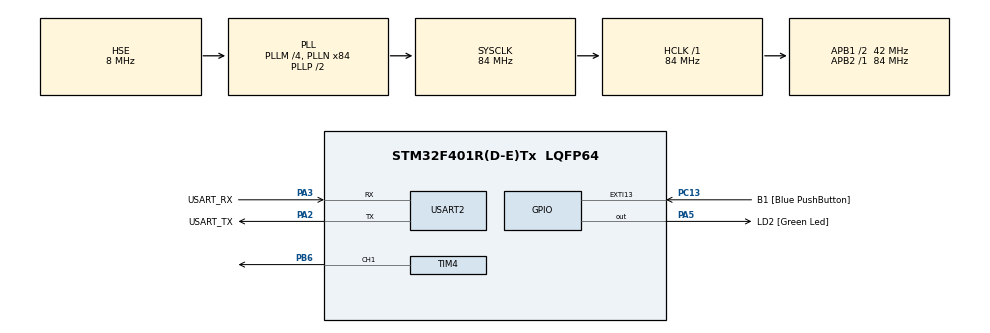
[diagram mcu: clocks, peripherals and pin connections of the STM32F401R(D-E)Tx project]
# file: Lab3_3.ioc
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Mcu.Family=STM32F4
Mcu.Name=STM32F401R(D-E)Tx
Mcu.Package=LQFP64
NVIC.PriorityGroup=NVIC_PRIORITYGROUP_2
NVIC.TIM1_UP_TIM10_IRQn=true\:2\:0\:true\:false\:true\:true\:true\:true
NVIC.TIM3_IRQn=true\:2\:0\:true\:false\:true\:true\:true\:true
NVIC.TIM4_IRQn=true\:2\:0\:true\:false\:true\:true\:true\:true
PA13.GPIO_Label=TMS
PA13.Mode=Serial_Wire
PA13.Signal=SYS_JTMS-SWDIO
PA14.GPIO_Label=TCK
PA14.Mode=Serial_Wire
PA14.Signal=SYS_JTCK-SWCLK
PA2.GPIO_Label=USART_TX
PA2.GPIO_Mode=GPIO_MODE_AF_PP
PA2.GPIO_PuPd=GPIO_NOPULL
PA2.GPIO_Speed=GPIO_SPEED_FREQ_LOW
PA2.Mode=Asynchronous
PA2.Signal=USART2_TX
PA3.GPIO_Label=USART_RX
PA3.GPIO_Mode=GPIO_MODE_AF_PP
PA3.GPIO_PuPd=GPIO_NOPULL
PA3.GPIO_Speed=GPIO_SPEED_FREQ_LOW
PA3.Mode=Asynchronous
PA3.Signal=USART2_RX
PA5.GPIO_Label=LD2 [Green Led]
PA5.GPIO_Mode=GPIO_MODE_OUTPUT_PP
PA5.GPIO_PuPd=GPIO_NOPULL
PA5.GPIO_Speed=GPIO_SPEED_FREQ_LOW
PA5.Signal=GPIO_Output
PB3.GPIO_Label=SWO
PB3.Signal=SYS_JTDO-SWO
PB6.Signal=S_TIM4_CH1
PC13-ANTI_TAMP.GPIO_Label=B1 [Blue PushButton]
PC13-ANTI_TAMP.GPIO_ModeDefaultEXTI=GPIO_MODE_IT_FALLING
PC13-ANTI_TAMP.GPIO_PuPd=GPIO_NOPULL
PC13-ANTI_TAMP.Signal=GPXTI13
PC14-OSC32_IN.Mode=LSE-External-Oscillator
PC14-OSC32_IN.Signal=RCC_OSC32_IN
PC15-OSC32_OUT.Mode=LSE-External-Oscillator
PC15-OSC32_OUT.Signal=RCC_OSC32_OUT
PH0\ -\ OSC_IN.Mode=HSE-External-Clock-Source
PH0\ -\ OSC_IN.Signal=RCC_OSC_IN
PH1\ -\ OSC_OUT.Mode=HSE-External-Clock-Source
PH1\ -\ OSC_OUT.Signal=RCC_OSC_OUT
ProjectManager.HeapSize=0x200
ProjectManager.StackSize=0x400
ProjectManager.TargetToolchain=STM32CubeIDE
RCC.48MHZClocksFreq_Value=24000000
RCC.AHBFreq_Value=84000000
RCC.APB1CLKDivider=RCC_HCLK_DIV2
RCC.APB1Freq_Value=42000000
RCC.APB1TimFreq_Value=84000000
RCC.APB2Freq_Value=84000000
RCC.APB2TimFreq_Value=84000000
RCC.CortexFreq_Value=84000000
RCC.HCLKFreq_Value=84000000
RCC.HSE_VALUE=8000000
RCC.HSI_VALUE=16000000
RCC.PLLM=4
RCC.PLLN=84
RCC.PLLQ=7
RCC.PLLSourceVirtual=RCC_PLLSOURCE_HSE
RCC.SYSCLKFreq_VALUE=84000000
RCC.SYSCLKSource=RCC_SYSCLKSOURCE_PLLCLK
RCC.VCOOutputFreq_Value=168000000
SH.S_TIM4_CH1.0=TIM4_CH1,PWM Generation1 CH1
TIM10.Period=9998
TIM10.Prescaler=8399
TIM3.Period=4904
TIM3.Prescaler=8399
TIM4.Channel-PWM\ Generation1\ CH1=TIM_CHANNEL_1
TIM4.Period=4999
TIM4.Prescaler=8399
USART2.VirtualMode=VM_ASYNC
VP_TIM10_VS_ClockSourceINT.Mode=Enable_Timer
VP_TIM3_VS_ClockSourceINT.Mode=Internal
VP_TIM4_VS_ClockSourceINT.Mode=Internal
board=NUCLEO-F401RE

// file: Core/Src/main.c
/* USER CODE BEGIN Header */
/**
  ******************************************************************************
  * @file           : main.c
  * @brief          : Main program body
  ******************************************************************************
  * @attention
  *
  * Copyright (c) 2023 STMicroelectronics.
  * All rights reserved.
  *
  * This software is licensed under terms that can be found in the LICENSE file
  * in the root directory of this software component.
  * If no LICENSE file comes with this software, it is provided AS-IS.
  *
  ******************************************************************************
  */
/* USER CODE END Header */
#include "main.h"

TIM_HandleTypeDef htim3;
TIM_HandleTypeDef htim4;
TIM_HandleTypeDef htim10;

UART_HandleTypeDef huart2;

void SystemClock_Config(void);
static void MX_GPIO_Init(void);
static void MX_USART2_UART_Init(void);
static void MX_TIM4_Init(void);
static void MX_TIM3_Init(void);
static void MX_TIM10_Init(void);

int main(void)
{
  /* USER CODE BEGIN 1 */
	uint16_t timer_val;
  /* USER CODE END 1 */

  /* MCU Configuration--------------------------------------------------------*/

  /* Reset of all peripherals, Initializes the Flash interface and the Systick. */
  HAL_Init();

  /* Configure the system clock */
  SystemClock_Config();

  /* Initialize all configured peripherals */
  MX_GPIO_Init();
  MX_USART2_UART_Init();
  MX_TIM4_Init();
  MX_TIM3_Init();
  MX_TIM10_Init();
  /* USER CODE BEGIN 2 */

//  HAL_TIM_Base_Start(&htim4);
//  timer_val = __HAL_TIM_GET_COUNTER(&htim4);

  HAL_TIM_Base_Start_IT(&htim4);

  /* USER CODE END 2 */

  /* Infinite loop */
  /* USER CODE BEGIN WHILE */
  while (1)
  {
//	  if(__HAL_TIM_GET_COUNTER(&htim4) - timer_val >= 10000){
//		  HAL_GPIO_TogglePin(GPIOA, GPIO_PIN_5);
//		  timer_val = __HAL_TIM_GET_COUNTER(&htim4);
//	  }
    /* USER CODE END WHILE */

  }
}

void SystemClock_Config(void)
{
  RCC_OscInitTypeDef RCC_OscInitStruct = {0};
  RCC_ClkInitTypeDef RCC_ClkInitStruct = {0};

  /** Configure the main internal regulator output voltage
  */
  __HAL_RCC_PWR_CLK_ENABLE();
  __HAL_PWR_VOLTAGESCALING_CONFIG(PWR_REGULATOR_VOLTAGE_SCALE2);

  /** Initializes the RCC Oscillators according to the specified parameters
  * in the RCC_OscInitTypeDef structure.
  */
  RCC_OscInitStruct.OscillatorType = RCC_OSCILLATORTYPE_HSE;
  RCC_OscInitStruct.HSEState = RCC_HSE_BYPASS;
  RCC_OscInitStruct.PLL.PLLState = RCC_PLL_ON;
  RCC_OscInitStruct.PLL.PLLSource = RCC_PLLSOURCE_HSE;
  RCC_OscInitStruct.PLL.PLLM = 4;
  RCC_OscInitStruct.PLL.PLLN = 84;
  RCC_OscInitStruct.PLL.PLLP = RCC_PLLP_DIV2;
  RCC_OscInitStruct.PLL.PLLQ = 7;
  if (HAL_RCC_OscConfig(&RCC_OscInitStruct) != HAL_OK)
  {
    Error_Handler();
  }

  /** Initializes the CPU, AHB and APB buses clocks
  */
  RCC_ClkInitStruct.ClockType = RCC_CLOCKTYPE_HCLK|RCC_CLOCKTYPE_SYSCLK
                              |RCC_CLOCKTYPE_PCLK1|RCC_CLOCKTYPE_PCLK2;
  RCC_ClkInitStruct.SYSCLKSource = RCC_SYSCLKSOURCE_PLLCLK;
  RCC_ClkInitStruct.AHBCLKDivider = RCC_SYSCLK_DIV1;
  RCC_ClkInitStruct.APB1CLKDivider = RCC_HCLK_DIV2;
  RCC_ClkInitStruct.APB2CLKDivider = RCC_HCLK_DIV1;

  if (HAL_RCC_ClockConfig(&RCC_ClkInitStruct, FLASH_LATENCY_2) != HAL_OK)
  {
    Error_Handler();
  }
}

static void MX_TIM3_Init(void)
{

  TIM_ClockConfigTypeDef sClockSourceConfig = {0};
  TIM_MasterConfigTypeDef sMasterConfig = {0};

  htim3.Instance = TIM3;
  htim3.Init.Prescaler = 8399;
  htim3.Init.CounterMode = TIM_COUNTERMODE_UP;
  htim3.Init.Period = 4904;
  htim3.Init.ClockDivision = TIM_CLOCKDIVISION_DIV1;
  htim3.Init.AutoReloadPreload = TIM_AUTORELOAD_PRELOAD_DISABLE;
  if (HAL_TIM_Base_Init(&htim3) != HAL_OK)
  {
    Error_Handler();
  }
  sClockSourceConfig.ClockSource = TIM_CLOCKSOURCE_INTERNAL;
  if (HAL_TIM_ConfigClockSource(&htim3, &sClockSourceConfig) != HAL_OK)
  {
    Error_Handler();
  }
  sMasterConfig.MasterOutputTrigger = TIM_TRGO_RESET;
  sMasterConfig.MasterSlaveMode = TIM_MASTERSLAVEMODE_DISABLE;
  if (HAL_TIMEx_MasterConfigSynchronization(&htim3, &sMasterConfig) != HAL_OK)
  {
    Error_Handler();
  }

}

static void MX_TIM4_Init(void)
{

  TIM_ClockConfigTypeDef sClockSourceConfig = {0};
  TIM_MasterConfigTypeDef sMasterConfig = {0};
  TIM_OC_InitTypeDef sConfigOC = {0};

  htim4.Instance = TIM4;
  htim4.Init.Prescaler = 8399;
  htim4.Init.CounterMode = TIM_COUNTERMODE_UP;
  htim4.Init.Period = 4999;
  htim4.Init.ClockDivision = TIM_CLOCKDIVISION_DIV1;
  htim4.Init.AutoReloadPreload = TIM_AUTORELOAD_PRELOAD_DISABLE;
  if (HAL_TIM_Base_Init(&htim4) != HAL_OK)
  {
    Error_Handler();
  }
  sClockSourceConfig.ClockSource = TIM_CLOCKSOURCE_INTERNAL;
  if (HAL_TIM_ConfigClockSource(&htim4, &sClockSourceConfig) != HAL_OK)
  {
    Error_Handler();
  }
  if (HAL_TIM_PWM_Init(&htim4) != HAL_OK)
  {
    Error_Handler();
  }
  sMasterConfig.MasterOutputTrigger = TIM_TRGO_RESET;
  sMasterConfig.MasterSlaveMode = TIM_MASTERSLAVEMODE_DISABLE;
  if (HAL_TIMEx_MasterConfigSynchronization(&htim4, &sMasterConfig) != HAL_OK)
  {
    Error_Handler();
  }
  sConfigOC.OCMode = TIM_OCMODE_PWM1;
  sConfigOC.Pulse = 0;
  sConfigOC.OCPolarity = TIM_OCPOLARITY_HIGH;
  sConfigOC.OCFastMode = TIM_OCFAST_DISABLE;
  if (HAL_TIM_PWM_ConfigChannel(&htim4, &sConfigOC, TIM_CHANNEL_1) != HAL_OK)
  {
    Error_Handler();
  }
  HAL_TIM_MspPostInit(&htim4);

}

static void MX_TIM10_Init(void)
{

  htim10.Instance = TIM10;
  htim10.Init.Prescaler = 8399;
  htim10.Init.CounterMode = TIM_COUNTERMODE_UP;
  htim10.Init.Period = 9998;
  htim10.Init.ClockDivision = TIM_CLOCKDIVISION_DIV1;
  htim10.Init.AutoReloadPreload = TIM_AUTORELOAD_PRELOAD_DISABLE;
  if (HAL_TIM_Base_Init(&htim10) != HAL_OK)
  {
    Error_Handler();
  }

}

static void MX_USART2_UART_Init(void)
{

  huart2.Instance = USART2;
  huart2.Init.BaudRate = 115200;
  huart2.Init.WordLength = UART_WORDLENGTH_8B;
  huart2.Init.StopBits = UART_STOPBITS_1;
  huart2.Init.Parity = UART_PARITY_NONE;
  huart2.Init.Mode = UART_MODE_TX_RX;
  huart2.Init.HwFlowCtl = UART_HWCONTROL_NONE;
  huart2.Init.OverSampling = UART_OVERSAMPLING_16;
  if (HAL_UART_Init(&huart2) != HAL_OK)
  {
    Error_Handler();
  }

}

static void MX_GPIO_Init(void)
{
  GPIO_InitTypeDef GPIO_InitStruct = {0};

  /* GPIO Ports Clock Enable */
  __HAL_RCC_GPIOC_CLK_ENABLE();
  __HAL_RCC_GPIOH_CLK_ENABLE();
  __HAL_RCC_GPIOA_CLK_ENABLE();
  __HAL_RCC_GPIOB_CLK_ENABLE();

  /*Configure GPIO pin Output Level */
  HAL_GPIO_WritePin(LD2_GPIO_Port, LD2_Pin, GPIO_PIN_RESET);

  /*Configure GPIO pin : B1_Pin */
  GPIO_InitStruct.Pin = B1_Pin;
  GPIO_InitStruct.Mode = GPIO_MODE_IT_FALLING;
  GPIO_InitStruct.Pull = GPIO_NOPULL;
  HAL_GPIO_Init(B1_GPIO_Port, &GPIO_InitStruct);

  /*Configure GPIO pin : LD2_Pin */
  GPIO_InitStruct.Pin = LD2_Pin;
  GPIO_InitStruct.Mode = GPIO_MODE_OUTPUT_PP;
  GPIO_InitStruct.Pull = GPIO_NOPULL;
  GPIO_InitStruct.Speed = GPIO_SPEED_FREQ_LOW;
  HAL_GPIO_Init(LD2_GPIO_Port, &GPIO_InitStruct);

}

/* USER CODE BEGIN 4 */

void HAL_TIM_PeriodElapsedCallback(TIM_HandleTypeDef *htim){
	if(htim == &htim4){
		HAL_GPIO_TogglePin(GPIOA, GPIO_PIN_5);
	}
}

/* USER CODE END 4 */

void Error_Handler(void)
{
  __disable_irq();
  while (1)
  {
  }
}
